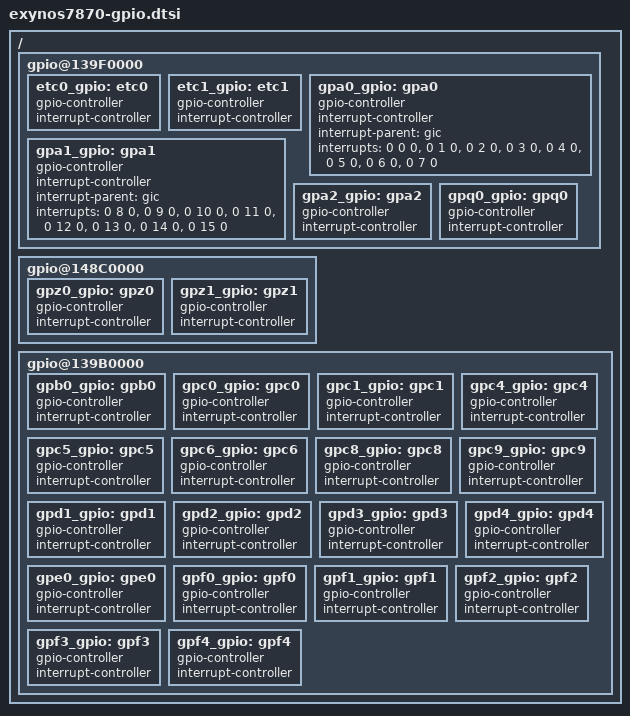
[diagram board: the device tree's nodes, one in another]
/*
 * Samsung's Exynos7880 SoC pin-mux and pin-config device tree source
 *
 * Copyright (c) 2014 Samsung Electronics Co., Ltd.
 *		http://www.samsung.com
 * Copyright (c) 2020 Dzmitry Sankouski (dsankouski@gmail.com)
 *
 * This program is free software; you can redistribute it and/or modify
 * it under the terms of the GNU General Public License version 2 as
 * published by the Free Software Foundation.
*/

/ {
	/* ALIVE */
	gpio@139F0000 {
		etc0_gpio: etc0 {
			gpio-controller;
			#gpio-cells = <2>;

			interrupt-controller;
			#interrupt-cells = <2>;
		};

		etc1_gpio: etc1 {
			gpio-controller;
			#gpio-cells = <2>;

			interrupt-controller;
			#interrupt-cells = <2>;
		};

		gpa0_gpio: gpa0 {
			gpio-controller;
			#gpio-cells = <2>;

			interrupt-controller;
			#interrupt-cells = <3>;
			interrupt-parent = <&gic>;
			interrupts = <0 0 0>, <0 1 0>, <0 2 0>, <0 3 0>,
				     <0 4 0>, <0 5 0>, <0 6 0>, <0 7 0>;
		};

		gpa1_gpio: gpa1 {
			gpio-controller;
			#gpio-cells = <2>;

			interrupt-controller;
			#interrupt-cells = <3>;
			interrupt-parent = <&gic>;
			interrupts = <0 8 0>, <0 9 0>, <0 10 0>, <0 11 0>,
				     <0 12 0>, <0 13 0>, <0 14 0>, <0 15 0>;
		};

		gpa2_gpio: gpa2 {
			gpio-controller;
			#gpio-cells = <2>;

			interrupt-controller;
			#interrupt-cells = <2>;
		};

		gpq0_gpio: gpq0 {
			gpio-controller;
			#gpio-cells = <2>;

			interrupt-controller;
			#interrupt-cells = <2>;
		};
	};

	gpio@148C0000 {
		gpz0_gpio: gpz0 {
			gpio-controller;
			#gpio-cells = <2>;

			interrupt-controller;
			#interrupt-cells = <2>;
		};

		gpz1_gpio: gpz1 {
			gpio-controller;
			#gpio-cells = <2>;

			interrupt-controller;
			#interrupt-cells = <2>;
		};
	};
	
    /* TOP */
	gpio@139B0000 {
		gpb0_gpio: gpb0 {
			gpio-controller;
			#gpio-cells = <2>;

			interrupt-controller;
			#interrupt-cells = <2>;
		};

		gpc0_gpio: gpc0 {
			gpio-controller;
			#gpio-cells = <2>;

			interrupt-controller;
			#interrupt-cells = <2>;
		};

		gpc1_gpio: gpc1 {
			gpio-controller;
			#gpio-cells = <2>;

			interrupt-controller;
			#interrupt-cells = <2>;
		};

		gpc4_gpio: gpc4 {
			gpio-controller;
			#gpio-cells = <2>;

			interrupt-controller;
			#interrupt-cells = <2>;
		};

		gpc5_gpio: gpc5 {
			gpio-controller;
			#gpio-cells = <2>;

			interrupt-controller;
			#interrupt-cells = <2>;
		};

		gpc6_gpio: gpc6 {
			gpio-controller;
			#gpio-cells = <2>;

			interrupt-controller;
			#interrupt-cells = <2>;
		};

		gpc8_gpio: gpc8 {
			gpio-controller;
			#gpio-cells = <2>;

			interrupt-controller;
			#interrupt-cells = <2>;
		};

		gpc9_gpio: gpc9 {
			gpio-controller;
			#gpio-cells = <2>;

			interrupt-controller;
			#interrupt-cells = <2>;
		};

		gpd1_gpio: gpd1 {
			gpio-controller;
			#gpio-cells = <2>;

			interrupt-controller;
			#interrupt-cells = <2>;
		};

		gpd2_gpio: gpd2 {
			gpio-controller;
			#gpio-cells = <2>;

			interrupt-controller;
			#interrupt-cells = <2>;
		};

		gpd3_gpio: gpd3 {
			gpio-controller;
			#gpio-cells = <2>;

			interrupt-controller;
			#interrupt-cells = <2>;
		};

		gpd4_gpio: gpd4 {
			gpio-controller;
			#gpio-cells = <2>;

			interrupt-controller;
			#interrupt-cells = <2>;
		};

		gpe0_gpio: gpe0 {
			gpio-controller;
			#gpio-cells = <2>;

			interrupt-controller;
			#interrupt-cells = <2>;
		};

		gpf0_gpio: gpf0 {
			gpio-controller;
			#gpio-cells = <2>;

			interrupt-controller;
			#interrupt-cells = <2>;
		};

		gpf1_gpio: gpf1 {
			gpio-controller;
			#gpio-cells = <2>;

			interrupt-controller;
			#interrupt-cells = <2>;
		};

		gpf2_gpio: gpf2 {
			gpio-controller;
			#gpio-cells = <2>;

			interrupt-controller;
			#interrupt-cells = <2>;
		};

		gpf3_gpio: gpf3 {
			gpio-controller;
			#gpio-cells = <2>;

			interrupt-controller;
			#interrupt-cells = <2>;
		};

		gpf4_gpio: gpf4 {
			gpio-controller;
			#gpio-cells = <2>;

			interrupt-controller;
			#interrupt-cells = <2>;
		};
	};
};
